# ATA5702M322 device description
Architecture: AVR8; Family: megaAVR
Registers are 8-bit, access not given, no defined reset value unless marked. A register's access mark holds for its fields unless they carry their own. Offsets are from the block's base; [hi:lo] are bit positions.

## TWI2
Instances: TWI2 0x00
0x1AA TW2BR — TWI2 Bit Rate Register
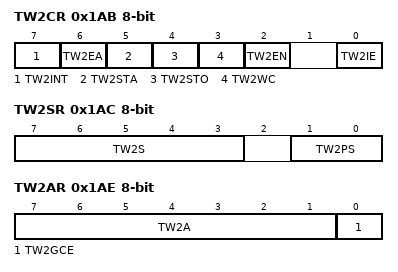
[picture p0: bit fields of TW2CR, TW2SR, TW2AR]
0x1AB TW2CR — TWI2 Control Register
  [7] TW2INT — TWI2 Interrupt Flag
  [6] TW2EA — TWI2 Enable Acknowledge
  [5] TW2STA — TWI2 START Condition
  [4] TW2STO — TWI2 STOP Condition
  [3] TW2WC — TWI2 Write Collision Flag
  [2] TW2EN — TWI2 Enable
  [0] TW2IE — TWI2 Interrupt Enable
0x1AC TW2SR — TWI2 Status Register
  [7:3] TW2S — TWI2 Status
  [1:0] TW2PS — TWI2 Prescaler
    0=1; 1=4; 2=16; 3=64
0x1AD TW2DR — TWI2 Data Register
0x1AE TW2AR — TWI2 (Slave) Address Register
  [7:1] TW2A — TWI2 (Slave) Address
  [0] TW2GCE — TWI2 General Call Recognition Enable
0x1AF TW2AMR — TWI2 Address Mask Register
  [7:1] TW2AM — TWI2 Address Mask

## TXDSP
Instances: TXDSP 0x00
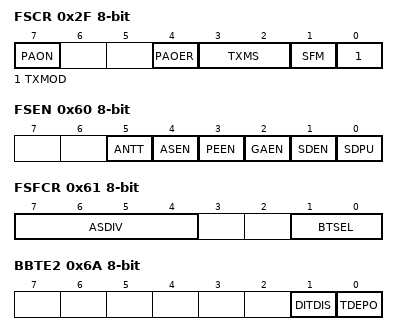
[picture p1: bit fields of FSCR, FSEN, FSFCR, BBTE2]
0x2F FSCR — Frequency Synthesizer Control Register
  [7] PAON — Power Amplifier Output is On
  [4] PAOER — Power Amplifier Output Enable Register
  [3:2] TXMS — Tx Modulation Source
    0=TXMOD_REGISTER; 1=TMDI_INPUT; 2=TX_MODULATOR_SERIAL_OUT
  [1] SFM — Select FSK Modulation
  [0] TXMOD — Tx Modulation
0x60 FSEN — Frequency Synthesizer Enable register
  [5] ANTT — Antenna Tuning Active
  [4] ASEN — ASK Shaping Enable
  [3] PEEN — Pre-emphasis Filtering Enable
  [2] GAEN — Gauss Filtering Enable
  [1] SDEN — Sigma-delta Modulator Enable
  [0] SDPU — Sigma-delta Modulator Power Up
0x61 FSFCR — Frequency Synthesizer Filter Control Register
  [7:4] ASDIV — ASK Shaping Divider
  [1:0] BTSEL — Gauss Filter BT Selection
    0=BT_2; 1=BT_1_5; 2=BT_1; 3=BT_0_5
0x62 GACDIV 16-bit bits used 12:0 — Gauss Clock Divider
0x64 FFREQ1L — Fractional Frequency 1 Setting, Low Byte
0x65 FFREQ1M — Fractional Frequency 1 Setting, Middle Byte
0x66 FFREQ1H bits used 1:0 — Fractional Frequency 1 Setting, High Byte
0x67 FFREQ2L — Fractional Frequency 2 Setting, Low Byte
0x68 FFREQ2M — Fractional Frequency 2 Setting, Middle Byte
0x69 FFREQ2H bits used 1:0 — Fractional Frequency 2 Setting, High Byte
0x6A BBTE2 — Base Band Test Enable 2
  [1] DITDIS — Dither Disable on Sigma Delta Modulator
  [0] TDEPO — Tx DSP External Pin Output

## TXM
Instances: TXM 0x00
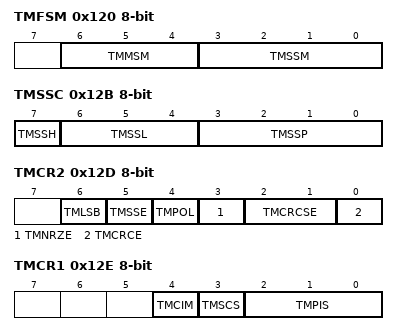
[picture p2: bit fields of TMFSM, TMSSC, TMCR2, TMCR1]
0x120 TMFSM — Tx Modulator Finite State Machine
  [6:4] TMMSM — Tx Modulator Master State Machine
  [3:0] TMSSM — Tx Modulator Sub State Machine
0x121 TMCRC 16-bit — Tx Modulator CRC Result
0x123 TMCSB — Tx Modulator CRC Skip Bit Number
0x124 TMCI 16-bit — Tx Modulator CRC Init Value
0x126 TMCP 16-bit — Tx Modulator CRC Polynomial
0x128 TMSHR — Tx Modulator Shift Register
0x129 TMTLL 16-bit bits used 11:0 — Tx Modulator Telegram Length Register
0x12B TMSSC — Tx Modulator Stop Sequence Configuration
  [7] TMSSH — Tx Modulator Stop Sequence Hold Mode
  [6:4] TMSSL — Tx Modulator Stop Sequence Length
  [3:0] TMSSP — Tx Modulator Stop Sequence Pattern
0x12C TMSR — Tx Modulator Status Register
  [0] TMTCF — Tx Modulator Transmission Complete Status Flag
0x12D TMCR2 — Tx Modulator Control Register 2
  [6] TMLSB — Tx Modulator Least Significant Bit First
  [5] TMSSE — Tx Modulator Stop Sequence Enable
  [4] TMPOL — Tx Modulator Polarity
  [3] TMNRZE — Tx Modulator NRZ Mode Enable
  [2:1] TMCRCSE — Tx Modulator CRC Select
    0=CRC_4_BIT; 1=CRC_8_BIT; 3=CRC_16_BIT
  [0] TMCRCE — Tx Modulator CRC Enable
0x12E TMCR1 — Tx Modulator Control Register 1
  [4] TMCIM — Tx Modulator Transmission Complete Interrupt Mask
  [3] TMSCS — Tx Modulator Serial Output Clock Select
  [2:0] TMPIS — Tx Modulator Port Interface Select
    0=PORT_D1; 1=M2_TOGGLE_REGISTER_TIMER2; 2=M3_TOGGLE_REGISTER_TIMER3; 3=M4_TOGGLE_REGISTER_TIMER4; 4=SO_TX_MODULATOR_SERIAL_OUTPUT; 5=M1_TOGGLE_REGISTER_TIMER1

## VX_MODE
Instances: VX_MODE 0x00
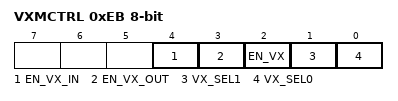
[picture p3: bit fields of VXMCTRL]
0xEB VXMCTRL — VX Mode Control Register
  [4] EN_VX_IN — Enable VX Inputs
  [3] EN_VX_OUT — Enable PB4 as an VX/VBAT Supply Output
  [2] EN_VX — Enable the VX_LDO
  [1] VX_SEL1 — Select VX voltage level
  [0] VX_SEL0 — Select VX voltage level

## FUSE
Instances: FUSE 0 in fuses
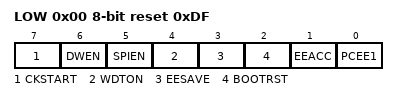
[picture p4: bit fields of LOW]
0x00 LOW reset 0xDF
  [7] CKSTART — MRC is selected during reset startup phase
  [6] DWEN — Debug Wire enable
  [5] SPIEN — Serial program downloading (SPI) enabled
  [4] WDTON — Watch-dog Timer always on
  [3] EESAVE — Preserve EEPROM memory through the Chip Erase cycle
  [2] BOOTRST — Select boot reset vector
  [1] EEACC — EEPROM Access Control
  [0] PCEE1 — Protect Customer EEPROM section

## LOCKBIT
Instances: LOCKBIT 0 in lockbits
0x00 LOCKBIT reset 0xFF
  [1:0] LB — Memory Lock
    0=PROG_VER_DISABLED (Further programming and verification disabled); 2=PROG_DISABLED (Further programming disabled); 3=NO_LOCK (No memory lock features enabled)
